# SF32LB58x register map
File version: 1.0
CPU: CM33 r0p1, little endian, MPU, FPU, 3 interrupt priority bits
Registers are 32-bit, read-write, reset 0x0 unless marked. A register's access mark holds for its fields unless they carry their own. Offsets are from the block's base; [hi:lo] are bit positions; lines under a group give offsets from that group; {n}, {i} and the like mark numbered series; 'fields as' and 'values as' point back to an identical list.

## FACC1
Base 0x40028000
Same registers: FACC2 0x5001F000
0x00 FACC_EN — facc enable ctrl
  [0] FACC_EN — 1:enable 0:stop
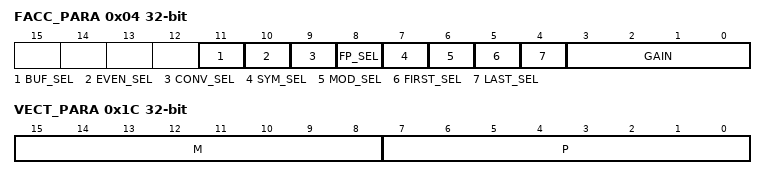
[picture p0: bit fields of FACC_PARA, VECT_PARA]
0x04 FACC_PARA — FACC parameter
  [11] BUF_SEL — 0:only support one group data 1:store intermediate data to external buffer,support cross processing of multiple groups data
  [10] EVEN_SEL — when sym_sel=1, this bit is effective 0: odd 1: even
  [9] CONV_SEL — 0: filter 1: convolution(only support fir mod)
  [8] FP_SEL — 0: 16bit 1: 8bit
  [7] SYM_SEL — 0:normal 1:symmetric(only support fir mod)
  [6] MOD_SEL — 0: fir 1: iir
  [5] FIRST_SEL — unused
  [4] LAST_SEL — when conv_sel=1 ,it is necrssary 0:other data block 1:last data block
  [3:0] GAIN — facc gain
0x08 SRC_ADDR — source address
0x0C DST_ADDR — destination address
0x10 BLK_LEN — source block length
  [31:0] BLK_LEN — block data byte(8bit) or word(16bit) number,count from 1
0x14 BUF_ADDR — buffer address
  [31:0] BUF_ADDR — intermediate data buffer address
0x18 DATA_SEQ — the sequence of the first data
  [31:0] DATA_SEQ — unused
0x1C VECT_PARA — vector number
  [15:8] M — IIR vector a step , count from 0
  [7:0] P — FIR/IIR vector b step , count from 0
0x20 VECT_B — vector b fifo
  [31:0] VECT_B — vector b
0x24 VECT_A — vector a fifo
  [31:0] VECT_A — vector a
0x28 VECT_CLR — vector fifo clr
  [0] VECT_CLR
0x2C INT_EN — interrupt enable
  [0] INT_EN
0x30 INT_STA — interrupt state
  [0] INT_STA
0x34 DBG_DATA — debug data
  [31:0] DEBUG_DATA — 13:inbuf_empty 12:inmem_full 11:inmem_empty 10:iir_en 9:iir_on 8:iir_ok 7:fir_end 6:conv_act 5:fir_on 4:blk_on 3~0 :ahb_state

## CRC1
Base 0x4008B000
Same registers: CRC2 0x50085000
0x00 DR — Data register
  [31:0] DR — Data register bits. This register is used to write new data to the CRC calculator. It holds the previous CRC calculation result when it is read. If the data size is less than 32 bits, the least significant bits are used to write/read the correct value.
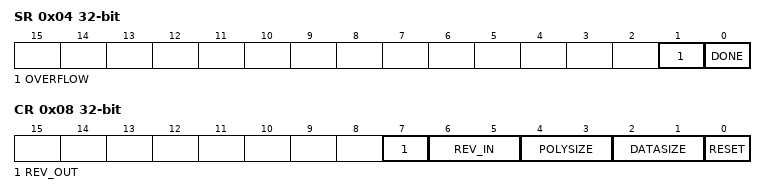
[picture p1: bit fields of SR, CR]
0x04 SR — Status register
  [1] OVERFLOW — Overflow when new data arrive while last calculation not done yet
  [0] DONE — Done flag. When DR written, done flag will be cleared automatically. The flag will assert after CRC operation of current DR finished.
0x08 CR — Control register
  [7] REV_OUT — Reverse output data This bit controls the reversal of the bit order of the output data. 0: Bit order not affected 1: Bit-reversed output format
  [6:5] REV_IN — Reverse input data These bits control the reversal of the bit order of the input data 00: Bit order not affected 01: Bit reversal done by byte 10: Bit reversal done by half-word 11: Bit reversal done by word
  [4:3] POLYSIZE — Polynomial size These bits control the size of the polynomial. 00: 32 bit polynomial 01: 16 bit polynomial 10: 8 bit polynomial 11: 7 bit polynomial
  [2:1] DATASIZE — Valid input data size These bits control the valid size of the input data. 00: lower 8-bit 01: lower 16-bit 10: lower 24-bit 11: all 32-bit
  [0] RESET — This bit is set by software to reset the CRC calculation unit and set the data register to the value stored in the CRC_INIT register. This bit can only be set, it is automatically cleared by hardware
0x10 INIT — Initial CRC value
  [31:0] INIT — Programmable initial CRC value
0x14 POL — CRC polynomial
  [31:0] POL — Programmable polynomial This register is used to write the coefficients of the polynomial to be used for CRC calculation. If the polynomial size is less than 32 bits, the least significant bits have to be used to program the correct value.

## LPSYS_PINMUX
Base 0x50003000
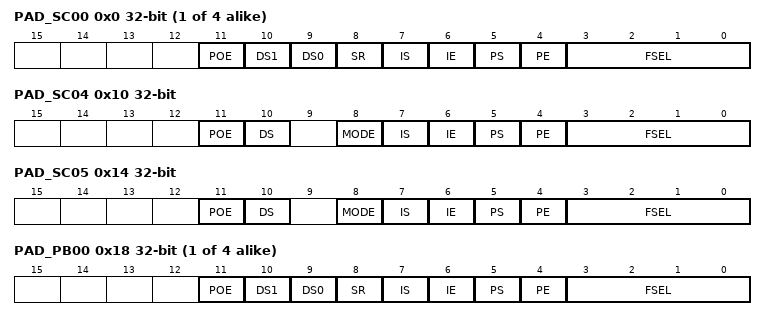
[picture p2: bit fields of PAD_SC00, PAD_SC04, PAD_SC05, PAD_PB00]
{0x0+4i} PAD_SC{i:02} (i=0..3)
  [11] POE — Parametric output enable. Logic LOW forces PO HIGH.
  [10] DS1 — Drive select 1. Used to select output drive strength.
  [9] DS0 — Drive select 0. Used to select output drive strength.
  [8] SR — Slew rate. Logic HIGH selects slow slew rate, logic LOW selects fast slew rate.
  [7] IS — Input select. Logic LOW selects CMOS input, and logic HIGH selects Schmitt input.
  [6] IE — Input enable. Logic HIGH enables the input buffer.
  [5] PS — Pull select. Logic HIGH selects pull-up, logic LOW selected pull-down.
  [4] PE — Pull enable. Logic HIGH enables weak pull device.
  [3:0] FSEL — Function Select
0x10 PAD_SC04
  [11] POE — Parametric output enable. Logic LOW forces PO HIGH.
  [10] DS — Drive select. Logic LOW selects 4mA drive, logic HIGH selects 20mA drive.
  [8] MODE — Mode select. Logic LOW enables GPIO mode, logic HIGH enables I2C mode.
  [7] IS — Input select. Logic LOW selects CMOS input, and logic HIGH selects Schmitt input.
  [6] IE — Input enable. Logic HIGH enables the input buffer.
  [5] PS — Pull select. Logic HIGH selects pull-up, logic LOW selected pull-down.
  [4] PE — Pull enable. Logic HIGH enables weak pull device.
  [3:0] FSEL — Function Select
0x14 PAD_SC05
  fields as PAD_SC04
{0x18+4i} PAD_PB{i:02} (i=0..3)
  fields as PAD_SC00
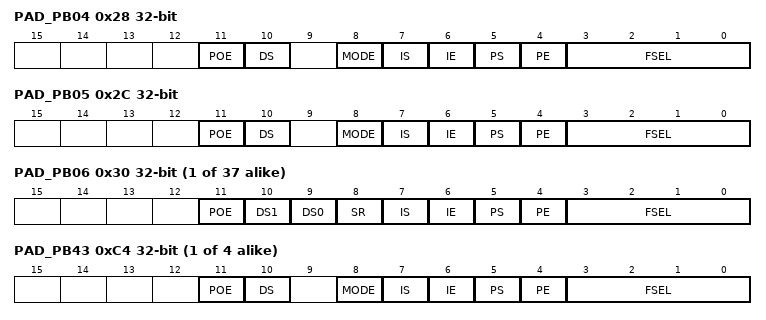
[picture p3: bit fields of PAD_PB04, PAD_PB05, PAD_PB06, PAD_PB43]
0x28 PAD_PB04
  fields as PAD_SC04
0x2C PAD_PB05
  fields as PAD_SC04
{0x18+4i} PAD_PB{i:02} (i=6..42)
  fields as PAD_SC00
{0x18+4i} PAD_PB{i} (i=43..46)
  fields as PAD_SC04
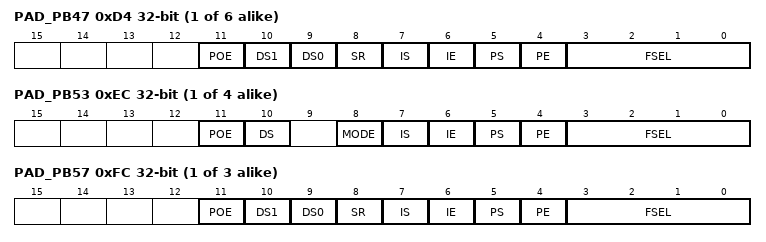
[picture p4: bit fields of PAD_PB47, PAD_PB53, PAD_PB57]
{0x18+4i} PAD_PB{i} (i=47..52)
  fields as PAD_SC00
{0x18+4i} PAD_PB{i} (i=53..56)
  fields as PAD_SC04
{0x18+4i} PAD_PB{i} (i=57..59)
  fields as PAD_SC00
